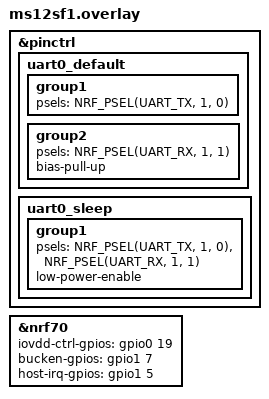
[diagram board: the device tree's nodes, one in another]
// / {
// 	nrf_radio_coex: coex {
// 		status = "okay";
// 		compatible = "nordic,nrf7002-coex";
//         status0-gpios = <&gpio0 20 GPIO_ACTIVE_HIGH>;
//         req-gpios = <&gpio0 22 GPIO_ACTIVE_HIGH>;
//         grant-gpios = <&gpio1 4 (GPIO_PULL_DOWN | GPIO_ACTIVE_LOW)>;
//         swctrl1-gpios = <&gpio1 6 GPIO_ACTIVE_HIGH>;
// 	};
// };

&pinctrl {
	uart0_default: uart0_default {
		group1 {
			psels = <NRF_PSEL(UART_TX, 1, 0)>;
		};

		group2 {
			psels = <NRF_PSEL(UART_RX, 1, 1)>;
			bias-pull-up;
		};
	};

	uart0_sleep: uart0_sleep {
		group1 {
			psels = <NRF_PSEL(UART_TX, 1, 0)>,
				<NRF_PSEL(UART_RX, 1, 1)>;
			low-power-enable;
		};
	};
};

&nrf70 {
    iovdd-ctrl-gpios = <&gpio0 19 (GPIO_ACTIVE_HIGH | GPIO_PULL_DOWN)>;
    bucken-gpios = <&gpio1 7 (GPIO_ACTIVE_HIGH | GPIO_PULL_DOWN)>;
    host-irq-gpios = <&gpio1 5 GPIO_ACTIVE_HIGH>;
};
